# XN11EXXX register map
File version: 1.3
CPU: CM0 r0p0, little endian, no MPU, no FPU, 2 interrupt priority bits
Registers are 32-bit, read-write, reset 0x0 unless marked. A register's access mark holds for its fields unless they carry their own. Offsets are from the block's base; [hi:lo] are bit positions; {n}, {i} and the like mark numbered series.

## WDT — Watch dog
Base 0x40004000
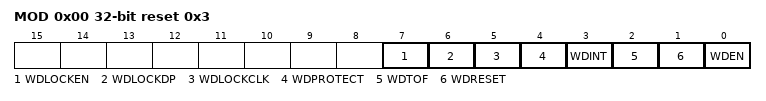
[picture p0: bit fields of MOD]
0x00 MOD reset 0x3 — WDT mode register
  [7] WDLOCKEN — Watchdog enables and reset lockout bit
  [6] WDLOCKDP — Power-down disable bit
  [5] WDLOCKCLK — Watchdog clock lock bit
  [4] WDPROTECT — Watchdog update mode
  [3] WDINT — To be filled
  [2] WDTOF — Watchdog time-out flag
  [1] WDRESET — Watchdog reset enable bit
  [0] WDEN — Watchdog enable bit
0x04 TC reset 0xFFFF — Watchdog timer constant register
  [23:0] WDTC — Watchdog time-out interval
0x08 FEED wo — Watchdog feed sequence register
  [7:0] WDFEED — Feed value should be 0xAA followed by 0x55
0x0C TV ro reset 0xFF — Watchdog timer value register
  [23:0] WDTV — Counter timer value
0x14 WARNINT — Watchdog Warning Interrupt compares value
  [9:0] WARNINT — Watchdog warning interrupt compare value
0x18 WINDOW reset 0xFFFFFF — Watchdog Window compares value
  [23:0] WDWINDOW — Watchdog window value

## UART0 — Universal asynchronous receiver/transmitter
Base 0x40008000
Same registers: UART1 0x4000C000
0x00 RDR ro — Receiver Data Register
  [7:0] RDR — Receiver Buffer Register
0x00 TDR wo — Transmit Data Register
  [7:0] TDR
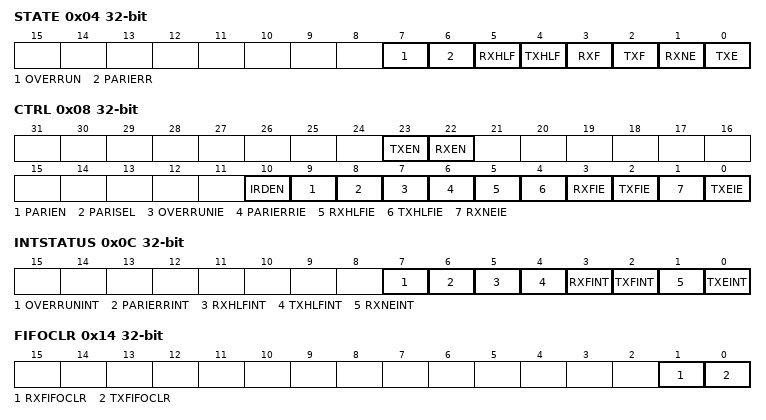
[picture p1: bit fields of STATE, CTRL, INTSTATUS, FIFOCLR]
0x04 STATE — State of current RX and TX FIFO
  [7] OVERRUN — Receiver overrun error flag
  [6] PARIERR — Receiver parity error flag
  [5] RXHLF — Receiver FIFO half full flag
  [4] TXHLF — Transmit FIFO half full flag
  [3] RXF — Receiver FIFO full flag
  [2] TXF — Transmit FIFO full flag
  [1] RXNE — Receiver FIFO not empty flag
  [0] TXE — Transmit FIFO empty flag
0x08 CTRL — Control UART interrupt enable and disable
  [23] TXEN — Enable UART TX
  [22] RXEN — Enable UART RX
  [10] IRDEN — Enable IrDN
  [9] PARIEN — Enable parity
  [8] PARISEL — Parity selection
  [7] OVERRUNIE — Overrun interrupt enable
  [6] PARIERRIE — Parity error interrupt enable
  [5] RXHLFIE — RX FIFO half full interrupt enable
  [4] TXHLFIE — TX FIFO half full interrupt enable
  [3] RXFIE — RX FIFO full interrupt enable
  [2] TXFIE — TX FIFO full interrupt enable
  [1] RXNEIE — RX FIFO empty interrupt enable
  [0] TXEIE — TX FIFO empty interrupt enable
0x0C INTSTATUS — UART RX/TX interrupt status
  [7] OVERRUNINT — The interrupt occurs when RX overrun error is detected
  [6] PARIERRINT — The interrupt occurs when RX parity check error is detected
  [5] RXHLFINT — The interrupt occurs when RX FIFO is half full.
  [4] TXHLFINT — The interrupt occurs when TX FIFO is half full.
  [3] RXFINT — The interrupt occurs when TX FIFO is full.
  [2] TXFINT — The interrupt occurs when TX FIFO is full.
  [1] RXNEINT — The interrupt occurs when received data.
  [0] TXEINT — The interrupt occurs when data transmit completed.
0x10 BAUDDIV reset 0x10 — UART Baud rate divider
  [19:0] BAUDDIV — Baud-rate generation pre-scalar divisor value
0x14 FIFOCLR wo — Clear TX and RX FIFO
  [1] RXFIFOCLR — Write 1 to clear RX FIFO
  [0] TXFIFOCLR — Write 1 to clear TX FIFO

## CT16B0 — 16 bits timer
Base 0x40010000
Same registers: CT16B1 0x40014000
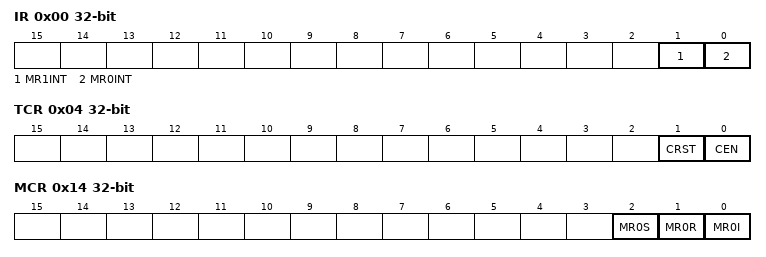
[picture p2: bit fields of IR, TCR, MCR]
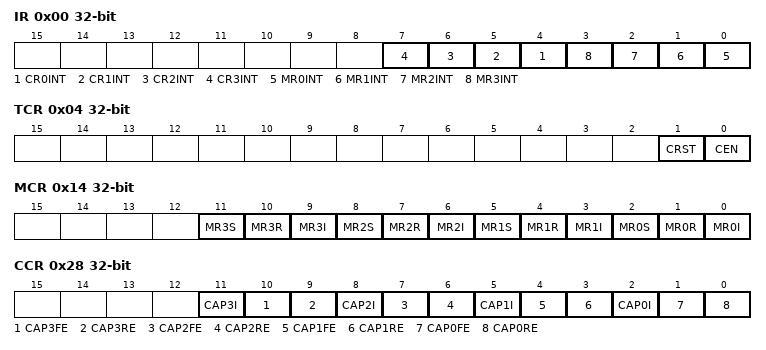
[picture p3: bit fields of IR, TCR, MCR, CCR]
0x00 IR — Interrupt register
  [1] MR1INT — To be filled
  [0] MR0INT — interrupt flag for match channel 0
0x04 TCR — Timer control register
  [1] CRST — Counter reset
  [0] CEN — Counter enable
0x08 TC — Timer counter register
  [15:0] TC — Timer counter value
0x0C PR — Prescale register
  [15:0] PCVAL — Prescale value
0x10 PC — Prescale Counter register
  [15:0] PC — Prescale counter value
0x14 MCR — Match Control Register
  [2] MR0S — Stop on MR0
  [1] MR0R — Reset on MR0
  [0] MR0I — Interrupt on MR0
0x18 MR0 — Match register0
  [15:0] MATCH — Timer counter match value

## CT16B2 — 16 bits timer
Base 0x40018000
Same registers: CT16B3 0x4001C000
0x00 IR — Interrupt register
  [n+4] CR{n}INT (n=0..3) — Interrupt flag for capture channel {n} event
  [n] MR{n}INT (n=0..3) — Interrupt flag for match channel {n}
0x04 TCR — Timer control register
  [1] CRST — Counter reset
  [0] CEN — Counter enable
0x08 TC — Timer counter register
  [15:0] TC — Timer counter value
0x0C PR — Prescale register
  [15:0] PCVAL — Prescale value
0x10 PC — Prescale Counter register
  [15:0] PC — Prescale counter value
0x14 MCR — Match Control Register
  [3n+2] MR{n}S (n=0..3) — Stop on MR{n}
  [3n+1] MR{n}R (n=0..3) — Reset on MR{n}
  [3n] MR{n}I (n=0..3) — Interrupt on MR{n}
{0x18+4i} MR{i} (i=0..3) — Match register{i}
  [15:0] MATCH — Timer counter match value
0x28 CCR — Capture Control Register
  [11] CAP3I — Interrupt on comparator n edge output event
  [10] CAP3FE — Capture on comparator n edge output_falling edge
  [9] CAP3RE — Capture on comparator n edge output_rising edge
  [8] CAP2I — Interrupt on comparator n level output event
  [7] CAP2FE — Capture on comparator n level output_falling edge
  [6] CAP2RE — Capture on comparator n level output_rising edge
  [5] CAP1I — Interrupt on CT16Bn_CAP1 event
  [4] CAP1FE — Capture on CT16Bn_CAP1 falling edge
  [3] CAP1RE — Capture on CT16Bn_CAP1 rising edge
  [2] CAP0I — Interrupt on CT16Bn_CAP0 event
  [1] CAP0FE — Capture on CT16Bn_CAP0 falling edge
  [0] CAP0RE — Capture on CT16Bn_CAP0 rising edge
{0x2C+4i} CR{i} ro (i=0..3) — Capture register{i}
  [15:0] CAP — Timer counter capture value
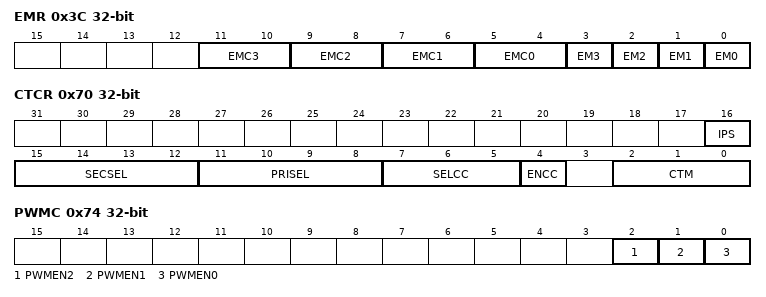
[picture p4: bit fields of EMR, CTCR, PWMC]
0x3C EMR — External match register
  [2n+5:2n+4] EMC{n} (n=0..3) — External match Control {n}
  [n] EM{n} (n=0..3) — External match {n}
0x70 CTCR — Counter control register
  [16] IPS — Secondary source input polarity select
  [15:12] SECSEL — Secondary clock source select
  [11:8] PRISEL — Primary clock source select
  [7:5] SELCC — Selection to clear timer and prescaler
  [4] ENCC — Enable SELCC slection to clear timer and prescaler
  [2:0] CTM — Counter/Timer Mode
0x74 PWMC — PWM Control Register
  [2] PWMEN2 — PWM mode enable for channel2.
  [1] PWMEN1 — PWM mode enable for channel1.
  [0] PWMEN0 — PWM mode enable for channel0.
